# SKEAZ1284 register map
File version: 1.6
SKEAZ1284 Freescale Microcontroller
Registers are 8-bit, read-write, reset 0x0 unless marked. A register's access mark holds for its fields unless they carry their own. Offsets are from the block's base; lines under a group give offsets from that group; [hi:lo] are bit positions; {n}, {i} and the like mark numbered series; 'fields as' and 'values as' point back to an identical list; <NAME> marks a mode.

## Memory map
0x00000400 FTMRE_FlashConfig size 0x10 — Flash configuration field
0x40020000 FTMRE blocks up to offset 0x10 — Flash Memory
0x40024000 MSCAN size 0x40 — Freescale's Scalable Controller Area Network
0x40031000 IRQ size 0x1 — Interrupt
0x40032000 CRC size 0xC — Cyclic Redundancy Check
0x40033000 PWT size 0x8 — Pulse Width Timer
0x40037000 PIT size 0x120 — Periodic Interrupt Timer
0x40038000 FTM0 size 0x70 — FlexTimer Module
0x40039000 FTM1 size 0x1C — FlexTimer Module
0x4003A000 FTM2 size 0x9C — FlexTimer Module
0x4003B000 ADC size 0x20 — Analog-to-digital converter
0x4003D000 RTC size 0xC — Real-time counter
0x40048000 SIM size 0x28 — System Integration Module
0x40049000 PORT size 0x18 — Port control and interrupts
0x40052000 WDOG size 0x8 — Watchdog timer
0x40064000 ICS size 0x5 — Clock management
0x40065000 OSC size 0x1 — Oscillator
0x40066000 I2C0 size 0xC — Inter-Integrated Circuit
0x40067000 I2C1 size 0xC — Inter-Integrated Circuit
0x4006A000 UART0 size 0x8 — Universal Asynchronous Receiver/Transmitter (UART)
0x4006B000 UART1 size 0x8 — Universal Asynchronous Receiver/Transmitter (UART)
0x4006C000 UART2 size 0x8 — Universal Asynchronous Receiver/Transmitter (UART)
0x40073000 ACMP0 size 0x4 — Analog comparator
0x40074000 ACMP1 size 0x4 — Analog comparator
0x40076000 SPI0 size 0x8 — Serial Peripheral Interface
0x40077000 SPI1 size 0x8 — Serial Peripheral Interface
0x40079000 KBI0 size 0x10 — Keyboard interrupts
0x4007A000 KBI1 size 0x10 — Keyboard interrupts
0x4007D000 PMC size 0x2 — Power management
0x400FF000 GPIOA size 0x1C — General Purpose Input/Output
0x400FF040 GPIOB size 0x1C — General Purpose Input/Output
0x400FF080 GPIOC size 0x1C — General Purpose Input/Output
0xF0002000 ROM size 0x1000 — System ROM
0xF0003000 MCM blocks up to offset 0x10 — Core Platform Miscellaneous Control Module
0xF8000000 FGPIOA size 0x1C — General Purpose Input/Output
0xF8000040 FGPIOB size 0x1C — General Purpose Input/Output
0xF8000080 FGPIOC size 0x1C — General Purpose Input/Output

## Interrupts
5 INT_FTMRE (FTMRE)
6 INT_PMC (PMC)
7 INT_IRQ (IRQ)
8 INT_I2C0 (I2C0)
9 INT_I2C1 (I2C1)
10 INT_SPI0 (SPI0)
11 INT_SPI1 (SPI1)
12 INT_UART0 (UART0)
13 INT_UART1 (UART1)
14 INT_UART2 (UART2)
15 INT_ADC (ADC)
16 INT_ACMP0 (ACMP0)
17 INT_FTM0 (FTM0)
18 INT_FTM1 (FTM1)
19 INT_FTM2 (FTM2)
20 INT_RTC (RTC)
21 INT_ACMP1 (ACMP1)
22 INT_PIT_CH0 (PIT)
23 INT_PIT_CH1 (PIT)
24 INT_KBI0 (KBI0)
25 INT_KBI1 (KBI1)
27 INT_ICS (ICS)
28 INT_WDOG (WDOG)
29 INT_PWT (PWT)
30 INT_MSCAN_RX (MSCAN)
31 INT_MSCAN_TX (MSCAN)

## FTMRE_FlashConfig — Flash configuration field
Base 0x00000400; register names take the prefix NV_
{0x0+i} BACKKEY{i} ro reset 0xFF (i=0..7) — Backdoor Comparison Key {i}
  [7:0] KEY — Backdoor Comparison Key.
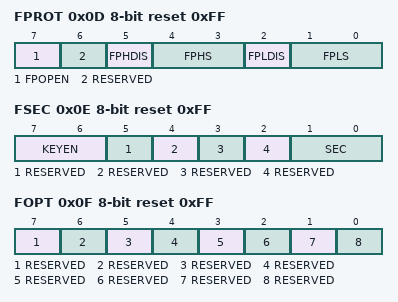
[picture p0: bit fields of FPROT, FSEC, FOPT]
0x0D FPROT ro reset 0xFF — Non-volatile P-Flash Protection Register
  [7] FPOPEN, [6] RESERVED, [5] FPHDIS, [4:3] FPHS, [2] FPLDIS, [1:0] FPLS
0x0E FSEC ro reset 0xFF — Non-volatile Flash Security Register
  [7:6] KEYEN — Backdoor Key Security Enable
  [5] RESERVED
  [4] RESERVED
  [3] RESERVED
  [2] RESERVED
  [1:0] SEC — Flash Security
0x0F FOPT ro reset 0xFF — Non-volatile Flash Option Register
  [7] RESERVED, [6] RESERVED, [5] RESERVED, [4] RESERVED, [3] RESERVED, [2] RESERVED, [1] RESERVED, [0] RESERVED

## FTMRE — Flash Memory
Base 0x40020000; register names take the prefix FTMRE_
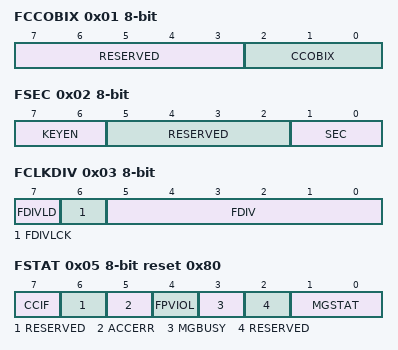
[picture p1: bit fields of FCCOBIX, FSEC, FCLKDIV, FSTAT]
0x01 FCCOBIX — Flash CCOB Index Register
  [7:3] RESERVED ro
  [2:0] CCOBIX — Common Command Register Index
0x02 FSEC ro reset not defined — Flash Security Register
  [7:6] KEYEN — Backdoor Key Security Enable Bits
    0=Disabled; 1=Disabled; 2=Enabled; 3=Disabled
  [5:2] RESERVED
  [1:0] SEC — Flash Security Bits
    0=Secured; 1=Secured; 2=Unsecured; 3=Secured
0x03 FCLKDIV — Flash Clock Divider Register
  [7] FDIVLD ro — Clock Divider Loaded
    0=FCLKDIV register has not been written since the last reset; 1=FCLKDIV register has been written since the last reset
  [6] FDIVLCK — Clock Divider Locked
    0=FDIV field is open for writing; 1=FDIV value is locked and cannot be changed. After the lock bit is set high, only reset can clear this bit and restore writability to the FDIV field in user mode.
  [5:0] FDIV — Clock Divider Bits
0x05 FSTAT reset 0x80 — Flash Status Register
  [7] CCIF — Command Complete Interrupt Flag
    0=Flash command is in progress; 1=Flash command has completed
  [6] RESERVED ro
  [5] ACCERR — Flash Access Error Flag
    0=No access error is detected; 1=Access error is detected
  [4] FPVIOL — Flash Protection Violation Flag
    0=No protection violation is detected; 1=Protection violation is detected
  [3] MGBUSY ro — Memory Controller Busy Flag
    0=Memory controller is idle; 1=Memory controller is busy executing a flash command (CCIF = 0)
  [2] RESERVED ro
  [1:0] MGSTAT ro — Memory Controller Command Completion Status Flag
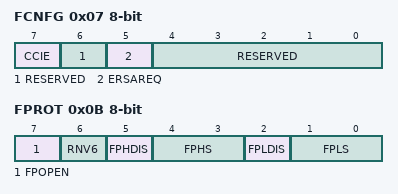
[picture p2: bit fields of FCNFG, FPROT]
0x07 FCNFG — Flash Configuration Register
  [7] CCIE — Command Complete Interrupt Enable
    0=Command complete interrupt is disabled; 1=An interrupt will be requested whenever the CCIF flag in the FSTAT register is set
  [6] RESERVED ro
  [5] ERSAREQ ro — Debugger Mass Erase Request
    0=No request or request complete; 1=Request to run the Erase All Blocks command verify the erased state program the security byte in the Flash Configuration Field to the unsecure state release MCU security by setting FSEC[SEC] to the unsecure state
  [4:0] RESERVED ro
0x08 FCCOBLO — Flash Common Command Object Register: Low
  [7:0] CCOB — Common Command Object Bit 7:0
0x09 FCCOBHI — Flash Common Command Object Register:High
  [7:0] CCOB — Common Command Object Bit 15:8
0x0B FPROT reset not defined — Flash Protection Register
  [7] FPOPEN — Flash Protection Operation Enable
    0=When FPOPEN is clear, the FPHDIS and FPLDIS fields define unprotected address ranges as specified by the corresponding FPHS and FPLS fields; 1=When FPOPEN is set, the FPHDIS and FPLDIS fields enable protection for the address range specified by the corresponding FPHS and FPLS fields
  [6] RNV6 ro — Reserved Nonvolatile Bit
  [5] FPHDIS — Flash Protection Higher Address Range Disable
    0=Protection/Unprotection enabled; 1=Protection/Unprotection disabled
  [4:3] FPHS — Flash Protection Higher Address Size
  [2] FPLDIS — Flash Protection Lower Address Range Disable
    values as FPHDIS
  [1:0] FPLS — Flash Protection Lower Address Size
0x0F FOPT ro reset not defined — Flash Option Register
  [7:0] NV — Nonvolatile Bits
